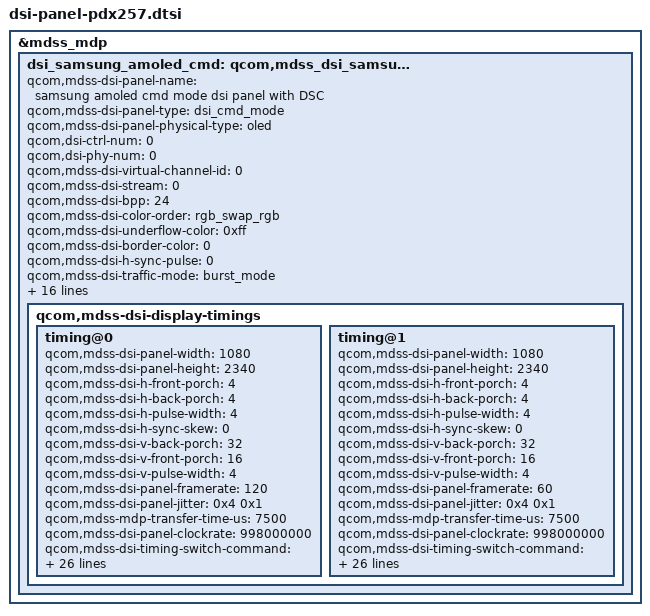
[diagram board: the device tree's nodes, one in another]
&mdss_mdp {
	dsi_samsung_amoled_cmd: qcom,mdss_dsi_samsung_fhd_plus_cmd {
		qcom,mdss-dsi-panel-name =
			"samsung amoled cmd mode dsi panel with DSC";
		qcom,mdss-dsi-panel-type = "dsi_cmd_mode";
		qcom,mdss-dsi-panel-physical-type = "oled";
		qcom,dsi-ctrl-num = <0>;
		qcom,dsi-phy-num = <0>;
		//qcom,mdss-dsi-dma-schedule-line = <15>;
		qcom,mdss-dsi-virtual-channel-id = <0>;
		qcom,mdss-dsi-stream = <0>;
		qcom,mdss-dsi-bpp = <24>;
		qcom,mdss-dsi-color-order = "rgb_swap_rgb";
		qcom,mdss-dsi-underflow-color = <0xff>;
		qcom,mdss-dsi-border-color = <0>;
		qcom,mdss-dsi-h-sync-pulse = <0>;
		//qcom,mdss-dsi-panel-mode-switch;
		qcom,mdss-dsi-traffic-mode = "burst_mode";
		qcom,mdss-dsi-lane-map = "lane_map_0123";
		qcom,mdss-dsi-bllp-eof-power-mode;
		qcom,mdss-dsi-bllp-power-mode;
		qcom,mdss-dsi-lane-0-state;
		qcom,mdss-dsi-lane-1-state;
		qcom,mdss-dsi-lane-2-state;
		qcom,mdss-dsi-lane-3-state;
		qcom,mdss-dsi-dma-trigger = "trigger_sw";
		qcom,mdss-dsi-mdp-trigger = "none";
		qcom,mdss-dsi-reset-sequence = <1 10>, <0 10>, <1 10>;
		//qcom,mdss-dsi-te-using-wd;
		//qcom,sde-has-idle-pc;
		qcom,mdss-dsi-te-pin-select = <1>;
		qcom,mdss-dsi-wr-mem-start = <0x2c>;
		qcom,mdss-dsi-wr-mem-continue = <0x3c>;
		qcom,mdss-dsi-te-dcs-command = <1>;
		qcom,mdss-dsi-te-check-enable;
		qcom,mdss-dsi-te-using-te-pin;

		qcom,mdss-dsi-display-timings {
			timing@0 {
			qcom,mdss-dsi-panel-width = <1080>;
			qcom,mdss-dsi-panel-height = <2340>;
			qcom,mdss-dsi-h-front-porch = <4>;
			qcom,mdss-dsi-h-back-porch = <4>;
			qcom,mdss-dsi-h-pulse-width = <4>;
			qcom,mdss-dsi-h-sync-skew = <0>;
			qcom,mdss-dsi-v-back-porch = <32>;
			qcom,mdss-dsi-v-front-porch = <16>;
			qcom,mdss-dsi-v-pulse-width = <4>;
			qcom,mdss-dsi-panel-framerate = <120>;
			qcom,mdss-dsi-panel-jitter = <0x4 0x1>;
			qcom,mdss-mdp-transfer-time-us = <7500>;
			qcom,mdss-dsi-panel-clockrate = <998000000>;
			qcom,mdss-dsi-timing-switch-command = [
				39 01 00 00 00 00 03 F0 5A 5A
				39 01 00 00 00 00 03 60 00 00
				15 01 00 00 00 00 02 F7 07
				39 01 00 00 00 00 03 F0 A5 A5

				39 01 00 00 00 00 03 F0 5A 5A
				39 01 00 00 00 00 03 FC 5A 5A
				39 01 00 00 00 00 02 FB 05
				39 01 00 00 00 00 02 F7 07
				39 01 00 00 00 00 03 F0 A5 A5
				39 01 00 00 00 00 03 FC A5 A5
			];
			qcom,mdss-dsi-on-command = [
				05 01 00 00 78 00 02 11 00
				15 01 00 00 00 00 02 35 00

				39 01 00 00 00 00 03 F0 5A 5A
				39 01 00 00 00 00 03 60 00 00
				15 01 00 00 00 00 02 F7 0F
				39 01 00 00 00 00 03 F0 A5 A5

				39 01 00 00 00 00 03 F0 5A 5A
				39 01 00 00 00 00 05 ED 4E AA 0F 4B
				39 01 00 00 00 00 03 F0 A5 A5

				39 01 00 00 00 00 03 F0 5A 5A
				39 01 00 00 00 00 03 B0 10 B1
				39 01 00 00 00 00 02 B1 05
				39 01 00 00 00 00 03 F0 A5 A5

				39 01 00 00 00 00 03 F0 5A 5A
				39 01 00 00 00 00 02 9D 01
				39 01 00 00 00 00 59 9E 11 00 00 89 30 80 09 24 04 38 00 24 02 1C 02 1C 02 00 02 3B 00 20 03 35 00 07 00 0E 03 34 02 D4 18 00 10 F0 03 0C 20 00 06 0B 0B 33 0E 1C 2A 38 46 54 62 69 70 77 79 7B 7D 7E 01 02 01 00 09 40 09 BE 19 FC 19 FA 19 F8 1A 38 1A 78 1A B6 2A B6 2A F4 2A F4 4B 34 63 74
				39 01 00 00 00 00 03 F0 A5 A5

				39 01 00 00 00 00 03 F0 5A 5A
				39 01 00 00 00 00 23 E1 A2 00 00 00 92 74 C1 80 00 00 00 00 FF 50 00 00 E1 00 00 52 5E 00 00 00 00 00 00 00 07 52 7C 5D 00 00
				39 01 00 00 00 00 03 99 27 A7
				39 01 00 00 00 00 03 B0 08 E1
				39 01 00 00 00 00 05 E1 00 00 00 00
				39 01 00 00 00 00 03 F0 A5 A5

				39 01 00 00 00 00 03 F0 5A 5A
				39 01 00 00 00 00 03 FC 5A 5A
				39 01 00 00 00 00 02 FB 05
				39 01 00 00 00 00 02 F7 07
				39 01 00 00 00 00 03 F0 A5 A5
				39 01 00 00 00 00 03 FC A5 A5

				39 01 00 00 00 00 05 2A 00 00 04 37
				39 01 00 00 00 00 05 2B 00 00 09 23
				15 01 00 00 00 00 02 53 28
				39 01 00 00 00 00 03 51 00 00
				15 01 00 00 00 00 02 55 00
				05 01 00 00 10 00 02 29 00
			];
			qcom,mdss-dsi-on-command-state = "dsi_lp_mode";
			qcom,mdss-dsi-off-command = [
				05 01 00 00 32 00 01 28
				05 01 00 00 78 00 01 10];
			qcom,mdss-dsi-off-command-state = "dsi_hs_mode";
			qcom,mdss-dsi-hbm-on-command = [
				39 01 00 00 00 00 03 51 08 00
				15 01 00 00 0A 00 02 53 E8
				39 01 00 00 00 00 03 51 0F FF];
			qcom,mdss-dsi-hbm-off-command = [
				39 01 00 00 00 00 03 51 0F FF
				15 01 00 00 0A 00 02 53 28
				39 01 00 00 00 00 03 51 07 FF];
			qcom,mdss-dsi-hbm-on-command-state = "dsi_lp_mode";
			qcom,mdss-dsi-hbm-off-command-state = "dsi_lp_mode";
			qcom,mdss-dsi-timing-switch-command-state = "dsi_lp_mode";
				qcom,compression-mode = "dsc";
				qcom,mdss-dsc-version = <0x11>;
				qcom,mdss-dsc-scr-version = <0x1>;
				qcom,mdss-dsc-slice-height = <36>;
				qcom,mdss-dsc-slice-width = <540>;
				qcom,mdss-dsc-slice-per-pkt = <2>;
				qcom,mdss-dsc-bit-per-component = <8>;
				qcom,mdss-dsc-bit-per-pixel = <8>;
				qcom,mdss-dsc-block-prediction-enable;
			};
			timing@1 {
				qcom,mdss-dsi-panel-width = <1080>;
				qcom,mdss-dsi-panel-height = <2340>;
				qcom,mdss-dsi-h-front-porch = <4>;
				qcom,mdss-dsi-h-back-porch = <4>;
				qcom,mdss-dsi-h-pulse-width = <4>;
				qcom,mdss-dsi-h-sync-skew = <0>;
				qcom,mdss-dsi-v-back-porch = <32>;
				qcom,mdss-dsi-v-front-porch = <16>;
				qcom,mdss-dsi-v-pulse-width = <4>;
				qcom,mdss-dsi-panel-framerate = <60>;
				qcom,mdss-dsi-panel-jitter = <0x4 0x1>;
				qcom,mdss-mdp-transfer-time-us = <7500>;
				qcom,mdss-dsi-panel-clockrate = <998000000>;
				qcom,mdss-dsi-timing-switch-command = [
					39 01 00 00 00 00 03 F0 5A 5A
					39 01 00 00 00 00 03 60 00 40
					15 01 00 00 00 00 02 F7 07
					39 01 00 00 00 00 03 F0 A5 A5

					39 01 00 00 00 00 03 F0 5A 5A
					39 01 00 00 00 00 03 FC 5A 5A
					39 01 00 00 00 00 02 FB 05
					39 01 00 00 00 00 02 F7 07
					39 01 00 00 00 00 03 F0 A5 A5
					39 01 00 00 00 00 03 FC A5 A5
				];
				qcom,mdss-dsi-on-command = [
					05 01 00 00 78 00 02 11 00
					15 01 00 00 00 00 02 35 00

					39 01 00 00 00 00 03 F0 5A 5A
					39 01 00 00 00 00 03 60 00 40
					15 01 00 00 00 00 02 F7 0F
					39 01 00 00 00 00 03 F0 A5 A5

					39 01 00 00 00 00 03 F0 5A 5A
					39 01 00 00 00 00 05 ED 4E AA 0F 4B
					39 01 00 00 00 00 03 F0 A5 A5

					39 01 00 00 00 00 03 F0 5A 5A
					39 01 00 00 00 00 03 B0 10 B1
					39 01 00 00 00 00 02 B1 05
					39 01 00 00 00 00 03 F0 A5 A5

					39 01 00 00 00 00 03 F0 5A 5A
					39 01 00 00 00 00 02 9D 01
					39 01 00 00 00 00 59 9E 11 00 00 89 30 80 09 24 04 38 00 24 02 1C 02 1C 02 00 02 3B 00 20 03 35 00 07 00 0E 03 34 02 D4 18 00 10 F0 03 0C 20 00 06 0B 0B 33 0E 1C 2A 38 46 54 62 69 70 77 79 7B 7D 7E 01 02 01 00 09 40 09 BE 19 FC 19 FA 19 F8 1A 38 1A 78 1A B6 2A B6 2A F4 2A F4 4B 34 63 74
					39 01 00 00 00 00 03 F0 A5 A5

					39 01 00 00 00 00 03 F0 5A 5A
					39 01 00 00 00 00 23 E1 A2 00 00 00 92 74 C1 80 00 00 00 00 FF 50 00 00 E1 00 00 52 5E 00 00 00 00 00 00 00 07 52 7C 5D 00 00
					39 01 00 00 00 00 03 99 27 A7
					39 01 00 00 00 00 03 B0 08 E1
					39 01 00 00 00 00 05 E1 00 00 00 00
					39 01 00 00 00 00 03 F0 A5 A5

					39 01 00 00 00 00 03 F0 5A 5A
					39 01 00 00 00 00 03 FC 5A 5A
					39 01 00 00 00 00 02 FB 05
					39 01 00 00 00 00 02 F7 07
					39 01 00 00 00 00 03 F0 A5 A5
					39 01 00 00 00 00 03 FC A5 A5

					39 01 00 00 00 00 05 2A 00 00 04 37
					39 01 00 00 00 00 05 2B 00 00 09 23
					15 01 00 00 00 00 02 53 28
					39 01 00 00 00 00 03 51 00 00
					15 01 00 00 00 00 02 55 00
					05 01 00 00 10 00 02 29 00
				];
				qcom,mdss-dsi-on-command-state = "dsi_lp_mode";
				qcom,mdss-dsi-off-command = [
					05 01 00 00 32 00 01 28
					05 01 00 00 78 00 01 10];
				qcom,mdss-dsi-off-command-state = "dsi_hs_mode";
				qcom,mdss-dsi-hbm-on-command = [
					39 01 00 00 00 00 03 51 08 00
					15 01 00 00 0A 00 02 53 E8
					39 01 00 00 00 00 03 51 0F FF];
				qcom,mdss-dsi-hbm-off-command = [
					39 01 00 00 00 00 03 51 0F FF
					15 01 00 00 0A 00 02 53 28
					39 01 00 00 00 00 03 51 07 FF];
				qcom,mdss-dsi-hbm-on-command-state = "dsi_lp_mode";
				qcom,mdss-dsi-hbm-off-command-state = "dsi_lp_mode";
				qcom,mdss-dsi-timing-switch-command-state = "dsi_lp_mode";
				qcom,compression-mode = "dsc";
				qcom,mdss-dsc-version = <0x11>;
				qcom,mdss-dsc-scr-version = <0x1>;
				qcom,mdss-dsc-slice-height = <36>;
				qcom,mdss-dsc-slice-width = <540>;
				qcom,mdss-dsc-slice-per-pkt = <2>;
				qcom,mdss-dsc-bit-per-component = <8>;
				qcom,mdss-dsc-bit-per-pixel = <8>;
				qcom,mdss-dsc-block-prediction-enable;
			};
		};
	};
};
